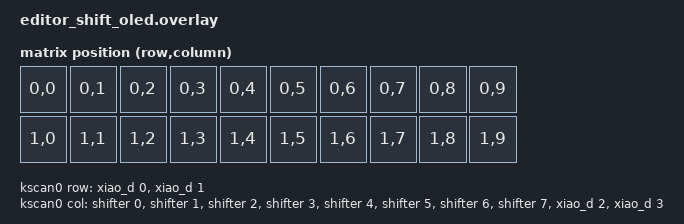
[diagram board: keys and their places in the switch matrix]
/* Generated by ZMK Editor from editor_shift_oled.editor.json. */

#include <dt-bindings/zmk/matrix_transform.h>
#include <physical_layouts.dtsi>

/ {
    chosen {
        zmk,kscan = &kscan0;
        zmk,physical-layout = &editor_shift_oled_layout;
    };

    kscan0: kscan {
        compatible = "zmk,kscan-gpio-matrix";
        wakeup-source;
        diode-direction = "col2row";

        row-gpios
            = <&xiao_d  0 (GPIO_ACTIVE_HIGH | GPIO_PULL_DOWN)>
            , <&xiao_d  1 (GPIO_ACTIVE_HIGH | GPIO_PULL_DOWN)>
            ;

        col-gpios
            = <&shifter  0 GPIO_ACTIVE_HIGH>
            , <&shifter  1 GPIO_ACTIVE_HIGH>
            , <&shifter  2 GPIO_ACTIVE_HIGH>
            , <&shifter  3 GPIO_ACTIVE_HIGH>
            , <&shifter  4 GPIO_ACTIVE_HIGH>
            , <&shifter  5 GPIO_ACTIVE_HIGH>
            , <&shifter  6 GPIO_ACTIVE_HIGH>
            , <&shifter  7 GPIO_ACTIVE_HIGH>
            , <&xiao_d  2 GPIO_ACTIVE_HIGH>
            , <&xiao_d  3 GPIO_ACTIVE_HIGH>
            ;
    };

    default_transform: keymap_transform_0 {
        compatible = "zmk,matrix-transform";
        rows = <2>;
        columns = <10>;
        map = <
RC(0,0) RC(0,1) RC(0,2) RC(0,3) RC(0,4) RC(0,5) RC(0,6) RC(0,7) RC(0,8) RC(0,9)
RC(1,0) RC(1,1) RC(1,2) RC(1,3) RC(1,4) RC(1,5) RC(1,6) RC(1,7) RC(1,8) RC(1,9)
        >;
    };

    editor_shift_oled_layout: editor_shift_oled_layout {
        compatible = "zmk,physical-layout";
        display-name = "Shift OLED";
        transform = <&default_transform>;

        keys  //                     w   h    x    y     rot   rx   ry
            = <&key_physical_attrs 100 100    0    0      0    0    0>
            , <&key_physical_attrs 100 100  100    0      0    0    0>
            , <&key_physical_attrs 100 100  200    0      0    0    0>
            , <&key_physical_attrs 100 100  300    0      0    0    0>
            , <&key_physical_attrs 100 100  400    0      0    0    0>
            , <&key_physical_attrs 100 100  500    0      0    0    0>
            , <&key_physical_attrs 100 100  600    0      0    0    0>
            , <&key_physical_attrs 100 100  700    0      0    0    0>
            , <&key_physical_attrs 100 100  800    0      0    0    0>
            , <&key_physical_attrs 100 100  900    0      0    0    0>
            , <&key_physical_attrs 100 100    0  100      0    0    0>
            , <&key_physical_attrs 100 100  100  100      0    0    0>
            , <&key_physical_attrs 100 100  200  100      0    0    0>
            , <&key_physical_attrs 100 100  300  100      0    0    0>
            , <&key_physical_attrs 100 100  400  100      0    0    0>
            , <&key_physical_attrs 100 100  500  100      0    0    0>
            , <&key_physical_attrs 100 100  600  100      0    0    0>
            , <&key_physical_attrs 100 100  700  100      0    0    0>
            , <&key_physical_attrs 100 100  800  100      0    0    0>
            , <&key_physical_attrs 100 100  900  100      0    0    0>
            ;
    };
};

&xiao_i2c {
    status = "okay";

    oled: ssd1306@3c {
        compatible = "solomon,ssd1306fb";
        reg = <0x3c>;
        width = <128>;
        height = <32>;
        segment-offset = <0>;
        page-offset = <0>;
        display-offset = <0>;
        multiplex-ratio = <31>;
        segment-remap;
        com-invdir;
        com-sequential;
        inversion-on;
        prechargep = <0x22>;
    };
};

/ {
    chosen {
        zephyr,display = &oled;
    };
};

&pinctrl {
    shift_register_spi_default: shift_register_spi_default {
        group1 {
            psels = <NRF_PSEL(SPIM_SCK, 1, 13)>,
                <NRF_PSEL(SPIM_MOSI, 1, 15)>;
        };
    };
    shift_register_spi_sleep: shift_register_spi_sleep {
        group1 {
            psels = <NRF_PSEL(SPIM_SCK, 1, 13)>,
                <NRF_PSEL(SPIM_MOSI, 1, 15)>;
            low-power-enable;
        };
    };
};

&spi2 {
    status = "okay";
    compatible = "nordic,nrf-spim";
    pinctrl-0 = <&shift_register_spi_default>;
    pinctrl-1 = <&shift_register_spi_sleep>;
    pinctrl-names = "default", "sleep";
    cs-gpios = <&xiao_d 9 GPIO_ACTIVE_LOW>;

    shifter: 595@0 {
        compatible = "zmk,gpio-595";
        status = "okay";
        gpio-controller;
        spi-max-frequency = <1000000>;
        reg = <0>;
        #gpio-cells = <2>;
        ngpios = <8>;
    };
};
